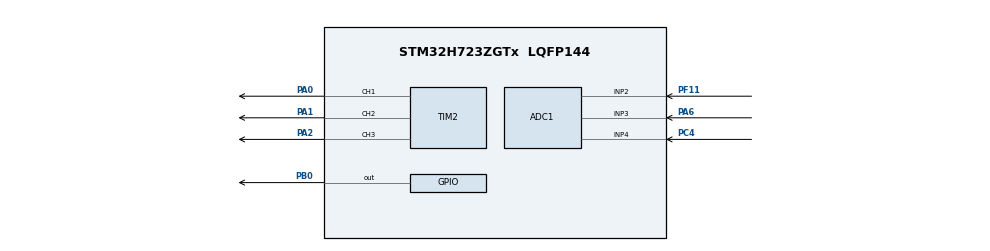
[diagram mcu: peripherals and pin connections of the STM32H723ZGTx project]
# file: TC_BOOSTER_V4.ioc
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ADC1.Channel-0\#ChannelRegularConversion=ADC_CHANNEL_2
ADC1.Channel-1\#ChannelRegularConversion=ADC_CHANNEL_3
ADC1.Channel-2\#ChannelRegularConversion=ADC_CHANNEL_4
ADC1.ContinuousConvMode=ENABLE
ADC1.ConversionDataManagement=ADC_CONVERSIONDATA_DMA_CIRCULAR
ADC1.EOCSelection=ADC_EOC_SEQ_CONV
ADC1.NbrOfConversion=3
ADC1.NbrOfConversionFlag=1
ADC1.OffsetNumber-0\#ChannelRegularConversion=ADC_OFFSET_NONE
ADC1.OffsetNumber-1\#ChannelRegularConversion=ADC_OFFSET_NONE
ADC1.OffsetNumber-2\#ChannelRegularConversion=ADC_OFFSET_NONE
ADC1.OffsetSignedSaturation-0\#ChannelRegularConversion=DISABLE
ADC1.OffsetSignedSaturation-1\#ChannelRegularConversion=DISABLE
ADC1.OffsetSignedSaturation-2\#ChannelRegularConversion=DISABLE
ADC1.Rank-0\#ChannelRegularConversion=1
ADC1.Rank-1\#ChannelRegularConversion=2
ADC1.Rank-2\#ChannelRegularConversion=3
ADC1.SamplingTime-0\#ChannelRegularConversion=ADC_SAMPLETIME_64CYCLES_5
ADC1.SamplingTime-1\#ChannelRegularConversion=ADC_SAMPLETIME_64CYCLES_5
ADC1.SamplingTime-2\#ChannelRegularConversion=ADC_SAMPLETIME_64CYCLES_5
ADC1.master=1
CORTEX_M7.default_mode_Activation=1
Dma.ADC1.0.Direction=DMA_PERIPH_TO_MEMORY
Dma.ADC1.0.EventEnable=DISABLE
Dma.ADC1.0.FIFOMode=DMA_FIFOMODE_DISABLE
Dma.ADC1.0.Instance=DMA1_Stream0
Dma.ADC1.0.MemDataAlignment=DMA_MDATAALIGN_HALFWORD
Dma.ADC1.0.MemInc=DMA_MINC_ENABLE
Dma.ADC1.0.Mode=DMA_CIRCULAR
Dma.ADC1.0.PeriphDataAlignment=DMA_PDATAALIGN_HALFWORD
Dma.ADC1.0.PeriphInc=DMA_PINC_DISABLE
Dma.ADC1.0.Polarity=HAL_DMAMUX_REQ_GEN_RISING
Dma.ADC1.0.Priority=DMA_PRIORITY_LOW
Dma.ADC1.0.RequestNumber=1
Dma.ADC1.0.SignalID=NONE
Dma.ADC1.0.SyncEnable=DISABLE
Dma.ADC1.0.SyncPolarity=HAL_DMAMUX_SYNC_NO_EVENT
Dma.ADC1.0.SyncRequestNumber=1
Dma.ADC1.0.SyncSignalID=NONE
Dma.Request0=ADC1
Mcu.Family=STM32H7
Mcu.Name=STM32H723ZGTx
Mcu.Package=LQFP144
NVIC.DMA1_Stream0_IRQn=true\:0\:0\:false\:false\:true\:false\:true\:true
NVIC.PriorityGroup=NVIC_PRIORITYGROUP_4
PA0.Signal=S_TIM2_CH1_ETR
PA1.Signal=S_TIM2_CH2
PA13(JTMS/SWDIO).GPIO_Label=SWDIO
PA13(JTMS/SWDIO).Signal=DEBUG_JTMS-SWDIO
PA14(JTCK/SWCLK).GPIO_Label=SWCLK
PA14(JTCK/SWCLK).Signal=DEBUG_JTCK-SWCLK
PA2.Signal=S_TIM2_CH3
PA6.Signal=ADCx_INP3
PB0.Signal=GPIO_Output
PC14-OSC32_IN.Signal=RCC_OSC32_IN
PC15-OSC32_OUT.Signal=RCC_OSC32_OUT
PC4.Signal=ADCx_INP4
PD8.GPIO_Label=STLK_VCP_RX
PD8.Signal=USART3_TX
PD9.GPIO_Label=STLK_VCP_TX
PD9.Signal=USART3_RX
PF11.Mode=IN2-Single-Ended
PF11.Signal=ADC1_INP2
ProjectManager.HeapSize=0x200
ProjectManager.StackSize=0x400
ProjectManager.TargetToolchain=CMake
RCC.ADCFreq_Value=48000000
RCC.APB1Freq_Value=96000000
RCC.APB2Freq_Value=96000000
RCC.APB3Freq_Value=96000000
RCC.APB4Freq_Value=96000000
RCC.CortexFreq_Value=192000000
RCC.D1PPRE=RCC_APB3_DIV2
RCC.D2PPRE1=RCC_APB1_DIV2
RCC.D2PPRE2=RCC_APB2_DIV2
RCC.D3PPRE=RCC_APB4_DIV2
RCC.DIVM1=4
RCC.DIVM2=4
RCC.DIVN1=12
RCC.DIVN2=12
RCC.DIVP1=1
RCC.DIVP2=4
RCC.DIVQ1=4
RCC.HCLKFreq_Value=192000000
RCC.HSE_VALUE=8000000
RCC.PLL2FRACN=0
RCC.PLLFRACN=0
RCC.SYSCLKFreq_VALUE=192000000
RCC.SYSCLKSource=RCC_SYSCLKSOURCE_PLLCLK
RCC.USBCLockSelection=RCC_USBCLKSOURCE_HSI48
RCC.USBFreq_Value=48000000
SH.ADCx_INP3.0=ADC1_INP3,IN3-Single-Ended
SH.ADCx_INP4.0=ADC1_INP4,IN4-Single-Ended
SH.S_TIM2_CH1_ETR.0=TIM2_CH1,PWM Generation1 CH1
SH.S_TIM2_CH2.0=TIM2_CH2,PWM Generation2 CH2
SH.S_TIM2_CH3.0=TIM2_CH3,PWM Generation3 CH3
TIM2.Channel-PWM\ Generation1\ CH1=TIM_CHANNEL_1
TIM2.Channel-PWM\ Generation2\ CH2=TIM_CHANNEL_2
TIM2.Channel-PWM\ Generation3\ CH3=TIM_CHANNEL_3
TIM6.Period=4999
TIM6.Prescaler=1919
VP_MEMORYMAP_VS_MEMORYMAP.Mode=CurAppReg
VP_TIM6_VS_ClockSourceINT.Mode=Enable_Timer
board=NUCLEO-H723ZG

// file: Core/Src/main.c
/* USER CODE BEGIN Header */
/**
  ******************************************************************************
  * @file           : main.c
  * @brief          : Main program body
  ******************************************************************************
  * @attention
  *
  * Copyright (c) 2026 STMicroelectronics.
  * All rights reserved.
  *
  * This software is licensed under terms that can be found in the LICENSE file
  * in the root directory of this software component.
  * If no LICENSE file comes with this software, it is provided AS-IS.
  *
  ******************************************************************************
  */
/* USER CODE END Header */
#include "main.h"

/* USER CODE BEGIN Includes */
#include "app.hpp"
/* USER CODE END Includes */

ADC_HandleTypeDef hadc1;
DMA_HandleTypeDef hdma_adc1;

TIM_HandleTypeDef htim2;
TIM_HandleTypeDef htim6;

void SystemClock_Config(void);
static void MPU_Config(void);
static void MX_GPIO_Init(void);
static void MX_DMA_Init(void);
static void MX_ADC1_Init(void);
static void MX_TIM2_Init(void);
static void MX_TIM6_Init(void);

int main(void)
{

  /* MPU Configuration--------------------------------------------------------*/
  MPU_Config();

  /* MCU Configuration--------------------------------------------------------*/

  /* Reset of all peripherals, Initializes the Flash interface and the Systick. */
  HAL_Init();

  /* Configure the system clock */
  SystemClock_Config();

  /* Initialize all configured peripherals */
  MX_GPIO_Init();
  MX_DMA_Init();
  MX_ADC1_Init();
  MX_TIM2_Init();
  MX_TIM6_Init();
  /* USER CODE BEGIN 2 */
  app_setup();
  /* USER CODE END 2 */

  /* Infinite loop */
  while (1)
  {
    app_loop();
  }
}

void SystemClock_Config(void)
{
  RCC_OscInitTypeDef RCC_OscInitStruct = {0};
  RCC_ClkInitTypeDef RCC_ClkInitStruct = {0};

  /** Supply configuration update enable
  */
  HAL_PWREx_ConfigSupply(PWR_LDO_SUPPLY);

  /** Configure the main internal regulator output voltage
  */
  __HAL_PWR_VOLTAGESCALING_CONFIG(PWR_REGULATOR_VOLTAGE_SCALE1);

  while(!__HAL_PWR_GET_FLAG(PWR_FLAG_VOSRDY)) {}

  /** Initializes the RCC Oscillators according to the specified parameters
  * in the RCC_OscInitTypeDef structure.
  */
  RCC_OscInitStruct.OscillatorType = RCC_OSCILLATORTYPE_HSI;
  RCC_OscInitStruct.HSIState = RCC_HSI_DIV1;
  RCC_OscInitStruct.HSICalibrationValue = 64;
  RCC_OscInitStruct.PLL.PLLState = RCC_PLL_ON;
  RCC_OscInitStruct.PLL.PLLSource = RCC_PLLSOURCE_HSI;
  RCC_OscInitStruct.PLL.PLLM = 4;
  RCC_OscInitStruct.PLL.PLLN = 12;
  RCC_OscInitStruct.PLL.PLLP = 1;
  RCC_OscInitStruct.PLL.PLLQ = 4;
  RCC_OscInitStruct.PLL.PLLR = 2;
  RCC_OscInitStruct.PLL.PLLRGE = RCC_PLL1VCIRANGE_3;
  RCC_OscInitStruct.PLL.PLLVCOSEL = RCC_PLL1VCOWIDE;
  RCC_OscInitStruct.PLL.PLLFRACN = 0;
  if (HAL_RCC_OscConfig(&RCC_OscInitStruct) != HAL_OK)
  {
    Error_Handler();
  }

  /** Initializes the CPU, AHB and APB buses clocks
  */
  RCC_ClkInitStruct.ClockType = RCC_CLOCKTYPE_HCLK|RCC_CLOCKTYPE_SYSCLK
                              |RCC_CLOCKTYPE_PCLK1|RCC_CLOCKTYPE_PCLK2
                              |RCC_CLOCKTYPE_D3PCLK1|RCC_CLOCKTYPE_D1PCLK1;
  RCC_ClkInitStruct.SYSCLKSource = RCC_SYSCLKSOURCE_PLLCLK;
  RCC_ClkInitStruct.SYSCLKDivider = RCC_SYSCLK_DIV1;
  RCC_ClkInitStruct.AHBCLKDivider = RCC_HCLK_DIV1;
  RCC_ClkInitStruct.APB3CLKDivider = RCC_APB3_DIV2;
  RCC_ClkInitStruct.APB1CLKDivider = RCC_APB1_DIV2;
  RCC_ClkInitStruct.APB2CLKDivider = RCC_APB2_DIV2;
  RCC_ClkInitStruct.APB4CLKDivider = RCC_APB4_DIV2;

  if (HAL_RCC_ClockConfig(&RCC_ClkInitStruct, FLASH_LATENCY_2) != HAL_OK)
  {
    Error_Handler();
  }
}

static void MX_ADC1_Init(void)
{

  ADC_MultiModeTypeDef multimode = {0};
  ADC_ChannelConfTypeDef sConfig = {0};

  /** Common config
  */
  hadc1.Instance = ADC1;
  hadc1.Init.ClockPrescaler = ADC_CLOCK_ASYNC_DIV1;
  hadc1.Init.Resolution = ADC_RESOLUTION_16B;
  hadc1.Init.ScanConvMode = ADC_SCAN_ENABLE;
  hadc1.Init.EOCSelection = ADC_EOC_SEQ_CONV;
  hadc1.Init.LowPowerAutoWait = DISABLE;
  hadc1.Init.ContinuousConvMode = ENABLE;
  hadc1.Init.NbrOfConversion = 3;
  hadc1.Init.DiscontinuousConvMode = DISABLE;
  hadc1.Init.ExternalTrigConv = ADC_SOFTWARE_START;
  hadc1.Init.ExternalTrigConvEdge = ADC_EXTERNALTRIGCONVEDGE_NONE;
  hadc1.Init.ConversionDataManagement = ADC_CONVERSIONDATA_DMA_CIRCULAR;
  hadc1.Init.Overrun = ADC_OVR_DATA_PRESERVED;
  hadc1.Init.LeftBitShift = ADC_LEFTBITSHIFT_NONE;
  hadc1.Init.OversamplingMode = DISABLE;
  hadc1.Init.Oversampling.Ratio = 1;
  if (HAL_ADC_Init(&hadc1) != HAL_OK)
  {
    Error_Handler();
  }

  /** Configure the ADC multi-mode
  */
  multimode.Mode = ADC_MODE_INDEPENDENT;
  if (HAL_ADCEx_MultiModeConfigChannel(&hadc1, &multimode) != HAL_OK)
  {
    Error_Handler();
  }

  /** Configure Regular Channel
  */
  sConfig.Channel = ADC_CHANNEL_2;
  sConfig.Rank = ADC_REGULAR_RANK_1;
  sConfig.SamplingTime = ADC_SAMPLETIME_64CYCLES_5;
  sConfig.SingleDiff = ADC_SINGLE_ENDED;
  sConfig.OffsetNumber = ADC_OFFSET_NONE;
  sConfig.Offset = 0;
  sConfig.OffsetSignedSaturation = DISABLE;
  if (HAL_ADC_ConfigChannel(&hadc1, &sConfig) != HAL_OK)
  {
    Error_Handler();
  }

  /** Configure Regular Channel
  */
  sConfig.Channel = ADC_CHANNEL_3;
  sConfig.Rank = ADC_REGULAR_RANK_2;
  if (HAL_ADC_ConfigChannel(&hadc1, &sConfig) != HAL_OK)
  {
    Error_Handler();
  }

  /** Configure Regular Channel
  */
  sConfig.Channel = ADC_CHANNEL_4;
  sConfig.Rank = ADC_REGULAR_RANK_3;
  if (HAL_ADC_ConfigChannel(&hadc1, &sConfig) != HAL_OK)
  {
    Error_Handler();
  }

}

static void MX_TIM2_Init(void)
{

  TIM_MasterConfigTypeDef sMasterConfig = {0};
  TIM_OC_InitTypeDef sConfigOC = {0};

  htim2.Instance = TIM2;
  htim2.Init.Prescaler = 0;
  htim2.Init.CounterMode = TIM_COUNTERMODE_UP;
  htim2.Init.Period = 4294967295;
  htim2.Init.ClockDivision = TIM_CLOCKDIVISION_DIV1;
  htim2.Init.AutoReloadPreload = TIM_AUTORELOAD_PRELOAD_DISABLE;
  if (HAL_TIM_PWM_Init(&htim2) != HAL_OK)
  {
    Error_Handler();
  }
  sMasterConfig.MasterOutputTrigger = TIM_TRGO_RESET;
  sMasterConfig.MasterSlaveMode = TIM_MASTERSLAVEMODE_DISABLE;
  if (HAL_TIMEx_MasterConfigSynchronization(&htim2, &sMasterConfig) != HAL_OK)
  {
    Error_Handler();
  }
  sConfigOC.OCMode = TIM_OCMODE_PWM1;
  sConfigOC.Pulse = 0;
  sConfigOC.OCPolarity = TIM_OCPOLARITY_HIGH;
  sConfigOC.OCFastMode = TIM_OCFAST_DISABLE;
  if (HAL_TIM_PWM_ConfigChannel(&htim2, &sConfigOC, TIM_CHANNEL_1) != HAL_OK)
  {
    Error_Handler();
  }
  if (HAL_TIM_PWM_ConfigChannel(&htim2, &sConfigOC, TIM_CHANNEL_2) != HAL_OK)
  {
    Error_Handler();
  }
  if (HAL_TIM_PWM_ConfigChannel(&htim2, &sConfigOC, TIM_CHANNEL_3) != HAL_OK)
  {
    Error_Handler();
  }
  HAL_TIM_MspPostInit(&htim2);

}

static void MX_TIM6_Init(void)
{

  TIM_MasterConfigTypeDef sMasterConfig = {0};

  htim6.Instance = TIM6;
  htim6.Init.Prescaler = 1919;
  htim6.Init.CounterMode = TIM_COUNTERMODE_UP;
  htim6.Init.Period = 4999;
  htim6.Init.AutoReloadPreload = TIM_AUTORELOAD_PRELOAD_DISABLE;
  if (HAL_TIM_Base_Init(&htim6) != HAL_OK)
  {
    Error_Handler();
  }
  sMasterConfig.MasterOutputTrigger = TIM_TRGO_RESET;
  sMasterConfig.MasterSlaveMode = TIM_MASTERSLAVEMODE_DISABLE;
  if (HAL_TIMEx_MasterConfigSynchronization(&htim6, &sMasterConfig) != HAL_OK)
  {
    Error_Handler();
  }

}

static void MX_DMA_Init(void)
{

  /* DMA controller clock enable */
  __HAL_RCC_DMA1_CLK_ENABLE();

  /* DMA interrupt init */
  /* DMA1_Stream0_IRQn interrupt configuration */
  HAL_NVIC_SetPriority(DMA1_Stream0_IRQn, 0, 0);
  HAL_NVIC_EnableIRQ(DMA1_Stream0_IRQn);

}

static void MX_GPIO_Init(void)
{
  GPIO_InitTypeDef GPIO_InitStruct = {0};

  /* GPIO Ports Clock Enable */
  __HAL_RCC_GPIOC_CLK_ENABLE();
  __HAL_RCC_GPIOA_CLK_ENABLE();
  __HAL_RCC_GPIOB_CLK_ENABLE();
  __HAL_RCC_GPIOF_CLK_ENABLE();
  __HAL_RCC_GPIOD_CLK_ENABLE();

  /*Configure GPIO pin Output Level */
  HAL_GPIO_WritePin(GPIOB, GPIO_PIN_0, GPIO_PIN_RESET);

  /*Configure GPIO pin : PB0 */
  GPIO_InitStruct.Pin = GPIO_PIN_0;
  GPIO_InitStruct.Mode = GPIO_MODE_OUTPUT_PP;
  GPIO_InitStruct.Pull = GPIO_NOPULL;
  GPIO_InitStruct.Speed = GPIO_SPEED_FREQ_LOW;
  HAL_GPIO_Init(GPIOB, &GPIO_InitStruct);

  /*Configure GPIO pins : STLK_VCP_RX_Pin STLK_VCP_TX_Pin */
  GPIO_InitStruct.Pin = STLK_VCP_RX_Pin|STLK_VCP_TX_Pin;
  GPIO_InitStruct.Mode = GPIO_MODE_AF_PP;
  GPIO_InitStruct.Pull = GPIO_NOPULL;
  GPIO_InitStruct.Speed = GPIO_SPEED_FREQ_LOW;
  GPIO_InitStruct.Alternate = GPIO_AF7_USART3;
  HAL_GPIO_Init(GPIOD, &GPIO_InitStruct);

}

 /* MPU Configuration */

void MPU_Config(void)
{
  MPU_Region_InitTypeDef MPU_InitStruct = {0};

  /* Disables the MPU */
  HAL_MPU_Disable();

  /** Initializes and configures the Region and the memory to be protected
  */
  MPU_InitStruct.Enable = MPU_REGION_ENABLE;
  MPU_InitStruct.Number = MPU_REGION_NUMBER0;
  MPU_InitStruct.BaseAddress = 0x0;
  MPU_InitStruct.Size = MPU_REGION_SIZE_4GB;
  MPU_InitStruct.SubRegionDisable = 0x87;
  MPU_InitStruct.TypeExtField = MPU_TEX_LEVEL0;
  MPU_InitStruct.AccessPermission = MPU_REGION_NO_ACCESS;
  MPU_InitStruct.DisableExec = MPU_INSTRUCTION_ACCESS_DISABLE;
  MPU_InitStruct.IsShareable = MPU_ACCESS_SHAREABLE;
  MPU_InitStruct.IsCacheable = MPU_ACCESS_NOT_CACHEABLE;
  MPU_InitStruct.IsBufferable = MPU_ACCESS_NOT_BUFFERABLE;

  HAL_MPU_ConfigRegion(&MPU_InitStruct);
  /* Enables the MPU */
  HAL_MPU_Enable(MPU_PRIVILEGED_DEFAULT);

}

void Error_Handler(void)
{
  __disable_irq();
  while (1)
  {
  }
}
